# R7FA6T2BD register map
Vendor: Renesas Electronics Corporation; Series: RA6; File version: 1.40.00
CPU: CM33 r0p4, little endian, MPU, FPU, VTOR, 4 interrupt priority bits, 96 interrupts
Registers are 32-bit, read-write, reset 0x0 unless marked. A register's access mark holds for its fields unless they carry their own. Offsets are from the block's base; [hi:lo] are bit positions.

## AGTW_B0 — Low Power Asynchronous General Purpose Timer 0
Base 0x400E8000
Same registers: AGTW_B1 0x400E8100
0x00 AGT reset 0xFFFFFFFF — AGT Counter Register
0x04 AGTCMA reset 0xFFFFFFFF — AGT CounterCompare Match A Register
0x08 AGTCMB reset 0xFFFFFFFF — AGT CounterCompare Match B Register
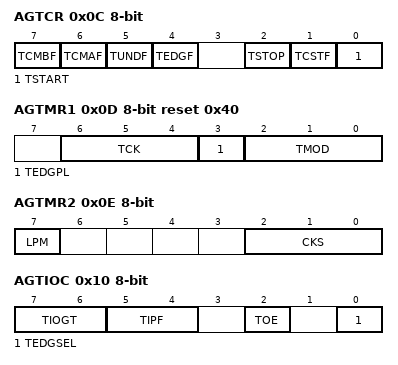
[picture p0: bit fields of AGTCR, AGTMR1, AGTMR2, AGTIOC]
0x0C AGTCR 8-bit — AGT Control Register
  [7] TCMBF — Compare Match B Flag
  [6] TCMAF — Compare Match A Flag
  [5] TUNDF — Underflow Flag
  [4] TEDGF — Active Edge Judgment Flag
  [2] TSTOP wo — AGT Count Forced Stop
  [1] TCSTF ro — AGT Count Status Flag
  [0] TSTART — AGT Count Start
0x0D AGTMR1 8-bit reset 0x40 — AGT Mode Register 1
  [6:4] TCK — Count Source
  [3] TEDGPL — Edge Polarity
  [2:0] TMOD — Operating Mode
0x0E AGTMR2 8-bit — AGT Mode Register 2
  [7] LPM — Low Power Mode
  [2:0] CKS — AGTLCLK Count Source Clock Frequency Division Ratio
0x10 AGTIOC 8-bit — AGT I/O Control Register
  [7:6] TIOGT — Count Control
  [5:4] TIPF — Input Filter
  [2] TOE — AGTWOn pin Output Enable
  [0] TEDGSEL — I/O Polarity Switch
0x11 AGTISR 8-bit — AGT Event Pin Select Register
  [2] EEPS — AGTWEEn Polarity Selection
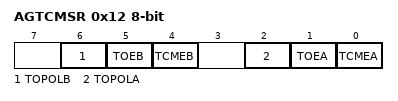
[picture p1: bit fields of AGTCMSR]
0x12 AGTCMSR 8-bit — AGT Compare Match Function Select Register
  [6] TOPOLB — AGTWOBn Pin Polarity Select
  [5] TOEB — AGTWOBn Pin Output Enable
  [4] TCMEB — AGT Compare Match B Register Enable
  [2] TOPOLA — AGTWOAn Pin Polarity Select
  [1] TOEA — AGTWOAn Pin Output Enable
  [0] TCMEA — AGT Compare Match A Register Enable
0x13 AGTIOSEL 8-bit — AGT Pin Select Register
  [4] TIES — AGTWIOn Pin Input Enable

## TSN — Temperature Sensor
Base 0x400F3000
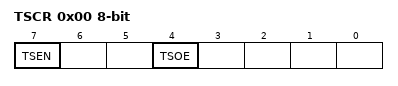
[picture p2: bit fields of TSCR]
0x00 TSCR 8-bit — Temperature Sensor Control Register
  [7] TSEN — Temperature Sensor Enable
  [4] TSOE — Temperature Sensor Output Enable

## ACMPHS0 — High,Speed Analog Comparator 0
Base 0x400F4000
Same registers: ACMPHS1 0x400F4100, ACMPHS2 0x400F4200, ACMPHS3 0x400F4300
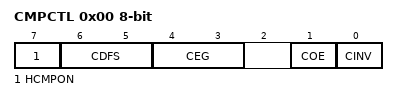
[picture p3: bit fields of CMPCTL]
0x00 CMPCTL 8-bit — Comparator Control Register
  [7] HCMPON — Comparator Operation Control
  [6:5] CDFS — Noise Filter Selection
  [4:3] CEG — Selection of Valid Edge (Edge Selector)
  [1] COE — Comparator Output Enable
  [0] CINV — Comparator Output Polarity Selection
0x04 CMPSEL0 8-bit — Comparator Input Select Register
  [3:0] CMPSEL — Comparator Input Selection
0x08 CMPSEL1 8-bit — Comparator Reference Voltage Select Register
  [3:0] CRVS — Reference Voltage Selection
0x0C CMPMON 8-bit ro — Comparator Output Monitor Register
  [0] CMPMON — Comparator Output Monitor
0x10 CPIOC 8-bit — Comparator Output Control Register
  [0] CPOE — Comparator Output Selection

## CRC — Cyclic Redundancy Check
Base 0x40108000
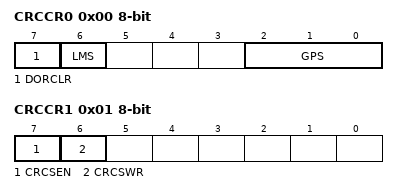
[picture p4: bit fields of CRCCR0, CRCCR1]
0x00 CRCCR0 8-bit — CRC Control Register 0
  [7] DORCLR wo — CRCDOR/CRCDOR_HA/CRCDOR_BY Register Clear
  [6] LMS — CRC Calculation Switching
  [2:0] GPS — CRC Generating Polynomial Switching
0x01 CRCCR1 8-bit — CRC Control Register 1
  [7] CRCSEN — Snoop Enable
  [6] CRCSWR — Snoop,On,Write/Read Switch
0x04 CRCDIR — CRC Data Input Register
0x04 CRCDIR_BY 8-bit (alternate view of CRCDIR) — CRC Data Input Register
0x08 CRCDOR — CRC Data Output Register
0x08 CRCDOR_HA 16-bit (alternate view of CRCDOR) — CRC Data Output Register
0x08 CRCDOR_BY 8-bit (alternate view of CRCDOR) — CRC Data Output Register
0x0C CRCSAR 16-bit — Snoop Address Register
  [13:0] CRCSA — Register Snoop Address

## DOC_B — Data Operation Circuit
Base 0x40109000
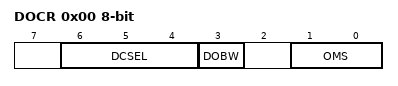
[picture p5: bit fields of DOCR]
0x00 DOCR 8-bit — DOC Control Register
  [6:4] DCSEL — Detection Condition Select
  [3] DOBW — Data Operation Bit Width Select
  [1:0] OMS — Operating Mode Select
0x04 DOSR 8-bit ro — DOC Flag Status Register
  [0] DOPCF — Data Operation Circuit Flag
0x08 DOSCR 8-bit wo — DOC Flag Status Clear Register
  [0] DOPCFCL — DOPCF Clear
0x0C DODIR — DOC Data Input Register
0x10 DODSR0 — DOC Data Setting Register 0
0x14 DODSR1 — DOC Data Setting Register 1
